# MSPM0G121X register map
Vendor: Texas Instruments; File version: Revised: 2025-10-06 10:58:04
CPU: CM0 r0p1, little endian, MPU, no FPU, 3 interrupt priority bits
Registers are 32-bit, read-write, reset 0x0 unless marked. A register's access mark holds for its fields unless they carry their own. Offsets are from the block's base; [hi:lo] are bit positions; lines under a group give offsets from that group; {n}, {i} and the like mark numbered series; 'fields as' and 'values as' point back to an identical list; <NAME> marks a mode.

## UC0_I2CC — PERIPHERALREGION
Base 0x40A26000
0x1000 UC0_I2CC_CLKDIV — Clock Divider
  [2:0] RATIO — Selects divide ratio of module clock Division factor 0 : DIV_BY_1 1 : DIV_BY_2 .... 63: DIV_BY_64
    0=DIV_BY_1 (Do not divide clock source); {v}=DIV_BY_{v+1} (Divide clock source by {v+1}) (v=1..7); {v}=DIV_BY_{v+1} (Divide clock source by 8) (v=60..63)
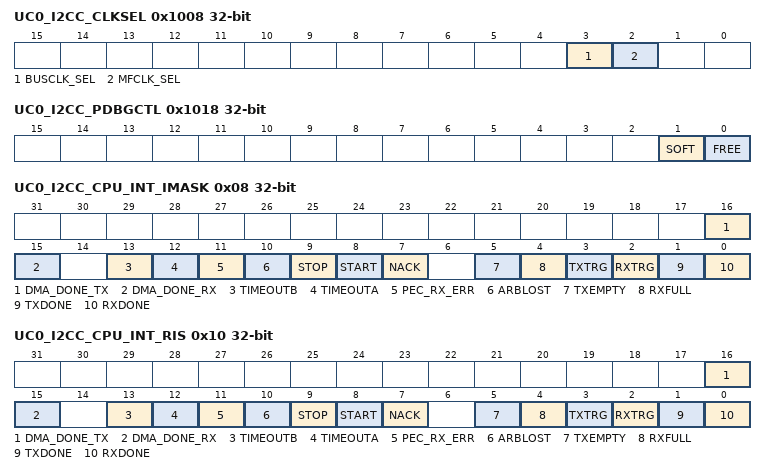
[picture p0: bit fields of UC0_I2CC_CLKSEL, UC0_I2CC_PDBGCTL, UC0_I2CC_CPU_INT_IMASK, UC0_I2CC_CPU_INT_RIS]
0x1008 UC0_I2CC_CLKSEL — Clock Select for Ultra Low Power peripherals
  [3] BUSCLK_SEL — Selects BUS CLK as clock source if enabled
    0=DISABLE (Does not select this clock as a source); 1=ENABLE (Select this clock as a source)
  [2] MFCLK_SEL — Selects MFCLK as clock source if enabled
    values as BUSCLK_SEL
0x1018 UC0_I2CC_PDBGCTL — Peripheral Debug Control
  [1] SOFT — Soft halt boundary control. This function is only available, if [FREE] is set to 'STOP'
    0=DEPRECATED (Not supported); 1=DELAYED (The peripheral blocks the debug freeze until it has reached a boundary where it can resume without corruption)
  [0] FREE — Free run control
    0=STOP (The peripheral freezes functionality while the Core Halted input is asserted and resumes when it is deasserted.); 1=RUN (The peripheral ignores the state of the Core Halted input)
{0x1020+0x2C*i} UC0_I2CC_CPU_INT[{i}] (i=0..0) group
  0x00 UC0_I2CC_IIDX ro — Interrupt index
    [7:0] STAT — I2C Module Interrupt Vector Value. This register provides the highes priority interrupt index. A read clears the corresponding interrupt flag in RIS and MISC. 15h-1Fh = Reserved
      0=NO_INTR (No interrupt pending); 1=RXDONEFG (Data received); 2=TXDONEFG (data transmitted); 3=RXTRG (Receive Trigger); 4=TXTRG (Transmit Trigger); 5=RXFULL (RX FIFO FULL Event/interrupt pending); 6=TXEMPTY (Transmit FIFO/Buffer Empty Event/interrupt pending); 8=NACKFG (Address/Data NACK); 9=STARTFG (Start Event); 10=STOPFG (Stop Event); 11=ARBLOSTFG (Arbitration Lost); 12=PEC_RX_ERR (PEC Receive Error Event); 13=TIMEOUTA (Timeout A Event); 14=TIMEOUTB (Timeout B Event); 16=DMA_DONE_RX (DMA DONE on Channel RX); 17=DMA_DONE_TX (DMA DONE on Channel TX); 19=DMA_PREIRQ_RX (DMA PRE IRQ INTERRUPT); 20=DMA_PREIRQ_TX (DMA PRE IRQ INTERRUPT)
  0x08 UC0_I2CC_CPU_INT_IMASK — Interrupt mask
    [16] DMA_DONE_TX — DMA Done on Event Channel TX
      0=CLR (Interrupt disabled); 1=SET (Set Interrupt Mask)
    [15] DMA_DONE_RX — DMA Done on Event Channel RX
      0=CLR (Interrupt disabled); 1=SET (Set Interrupt Mask)
    [13] TIMEOUTB — Timeout B Interrupt
      0=CLR (Clear Interrupt Mask); 1=SET (Set Interrupt Mask)
    [12] TIMEOUTA — TIMEOUTA interrupt
      0=CLR (Clear Interrupt Mask); 1=SET (Set Interrupt Mask)
    [11] PEC_RX_ERR — RX Pec Error Interrupt
      0=CLR (Clear Interrupt Mask); 1=SET (Set Interrupt Mask)
    [10] ARBLOST — Arbitration Lost interrupt
      0=CLR (Clear Interrupt Mask); 1=SET (Set Interrupt Mask)
    [9] STOP — STOP interrupt
      0=CLR (Clear Interrupt Mask); 1=SET (Set Interrupt Mask)
    [8] START — START interrupt
      0=CLR (Clear Interrupt Mask); 1=SET (Set Interrupt Mask)
    [7] NACK — NACK interrupt
      0=CLR (Clear Interrupt Mask); 1=SET (Set Interrupt Mask)
    [5] TXEMPTY — Transmit FIFO/Buffer Empty interrupt.
      0=CLR (Clear Interrupt Mask); 1=SET (Set Interrupt Mask)
    [4] RXFULL — RXFIFO full event
      0=CLR (Clear Interrupt Mask); 1=SET (Set Interrupt Mask)
    [3] TXTRG — Transmit Trigger
      0=CLR (Clear Interrupt Mask); 1=SET (Set Interrupt Mask)
    [2] RXTRG — Receive Trigger
      0=CLR (Clear Interrupt Mask); 1=SET (Set Interrupt Mask)
    [1] TXDONE — Transmit Transaction completed Interrupt
      0=CLR (Clear Interrupt Mask); 1=SET (Set Interrupt Mask)
    [0] RXDONE — RXDONE interrupt
      0=CLR (Clear Interrupt Mask); 1=SET (Set Interrupt Mask)
  0x10 UC0_I2CC_CPU_INT_RIS ro — Raw interrupt status
    [16] DMA_DONE_TX — DMA Done on Event Channel TX
      0=CLR (Interrupt disabled); 1=SET (Set Interrupt Mask)
    [15] DMA_DONE_RX — DMA Done on Event Channel RX
      0=CLR (Interrupt disabled); 1=SET (Set Interrupt Mask)
    [13] TIMEOUTB — Timeout B Interrupt
      0=CLR (Interrupt did not occur); 1=SET (Interrupt occured)
    [12] TIMEOUTA — Timeout A Interrupt
      0=CLR (Interrupt did not occur); 1=SET (Set Interrupt Mask)
    [11] PEC_RX_ERR — Receive PEC Error Interrupt: set when the calculated PEC does not match received PEC
      0=CLR (Interrupt did not occur); 1=SET (Interrupt Occured)
    [10] ARBLOST — Arbitration Lost Interrupt: in multi-controller systems, when this controller loses out during arbitration
      0=CLR (Interrupt did not occur); 1=SET (Set Interrupt Mask)
    [9] STOP — STOP Detection Interrupt
      0=CLR (Interrupt did not occur); 1=SET (Set Interrupt Mask)
    [8] START — START Detection Interrupt
      0=CLR (Interrupt did not occur); 1=SET (Set Interrupt Mask)
    [7] NACK — Address/Data NACK Interrupt: set when address or data nack is received
      0=CLR (Interrupt did not occur); 1=SET (Set Interrupt Mask)
    [5] TXEMPTY — Transmit FIFO Empty: set when Transmit FIFO is empty
      0=CLR (Interrupt did not occur); 1=SET (Interrupt occured)
    [4] RXFULL — RXFIFO full event. This interrupt is set when receive FIFO is full.
      0=CLR (Interrupt did not occur); 1=SET (Interrupt occured)
    [3] TXTRG — Transmit Trigger When FIFO is present, as per IFLS settings When FIFO is not present, trigger when transmit buffer is empty
      0=CLR (Clear Interrupt Mask); 1=SET (Set Interrupt Mask)
    [2] RXTRG — Receive Trigger When FIFO is present, as per IFLS settings when FIFO is not present, this indicates when buffer is full
      0=CLR (Clear Interrupt Mask); 1=SET (Set Interrupt Mask)
    [1] TXDONE — Transmit Done Interrupt: TXDONE interrupt is raised when a burst length completes Or, in case of quick command, when a quick command with R/Wn bit set to '0'
      0=CLR (Interrupt did not occur); 1=SET (Set Interrupt Mask)
    [0] RXDONE — Receive Done Interrupt: RXDONE interrupt is raised when a burst length completes Or, in case of quick command, when a quick command with R/Wn bit set to '1'
      0=CLR (Interrupt did not occur); 1=SET (Set Interrupt Mask)
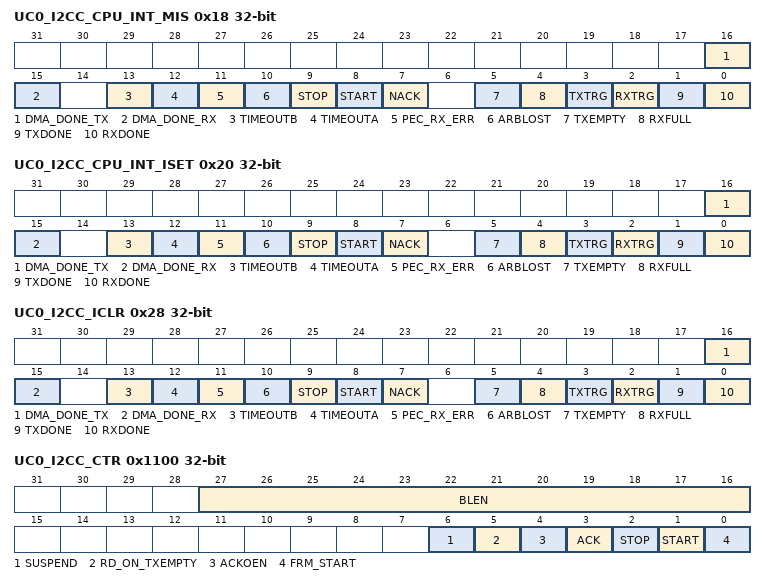
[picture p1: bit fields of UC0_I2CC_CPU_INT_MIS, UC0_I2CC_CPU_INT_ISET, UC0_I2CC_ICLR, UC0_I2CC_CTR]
  0x18 UC0_I2CC_CPU_INT_MIS ro — Masked interrupt status
    [16] DMA_DONE_TX — DMA Done on Event Channel TX
      0=CLR (Interrupt disabled); 1=SET (Set Interrupt Mask)
    [15] DMA_DONE_RX — DMA Done on Event Channel RX
      0=CLR (Interrupt disabled); 1=SET (Set Interrupt Mask)
    [13] TIMEOUTB — Timeout B Interrupt
      0=CLR (Clear interrupt mask); 1=SET (Set interrupt mask)
    [12] TIMEOUTA — Timeout A Interrupt
      0=CLR (Interrupt did not occur); 1=SET (Set Interrupt Mask)
    [11] PEC_RX_ERR — RX Pec Error Interrupt
      0=CLR (Clear interrupt mask); 1=SET (Set interrupt mask)
    [10] ARBLOST — Arbitration Lost Interrupt
      0=CLR (Interrupt did not occur); 1=SET (Set Interrupt Mask)
    [9] STOP — STOP Detection Interrupt
      0=CLR (Interrupt did not occur); 1=SET (Set Interrupt Mask)
    [8] START — START Detection Interrupt
      0=CLR (Interrupt did not occur); 1=SET (Set Interrupt Mask)
    [7] NACK — Address/Data NACK Interrupt
      0=CLR (Interrupt did not occur); 1=SET (Set Interrupt Mask)
    [5] TXEMPTY — Transmit FIFO Empty masked interrupt. This interrupt is set if all data in the Transmit FIFO have been shifted out and the transmit goes into idle mode.
      0=CLR (Interrupt did not occur); 1=SET (Interrupt occured)
    [4] RXFULL — Masked RXFIFO full event
      0=CLR (Interrupt did not occur); 1=SET (Interrupt occured)
    [3] TXTRG — Transmit Trigger
      0=CLR (Clear Interrupt Mask); 1=SET (Set Interrupt Mask)
    [2] RXTRG — Receive Trigger
      0=CLR (Clear Interrupt Mask); 1=SET (Set Interrupt Mask)
    [1] TXDONE — Transmit Transaction completed Interrupt
      0=CLR (Interrupt did not occur); 1=SET (Set Interrupt Mask)
    [0] RXDONE — Receive Data Interrupt
      0=CLR (Interrupt did not occur); 1=SET (Set Interrupt Mask)
  0x20 UC0_I2CC_CPU_INT_ISET wo — Interrupt set
    [16] DMA_DONE_TX — DMA Done on Event Channel TX
      0=NO_EFFECT (Interrupt disabled); 1=SET (Set Interrupt Mask)
    [15] DMA_DONE_RX — DMA Done on Event Channel RX
      0=NO_EFFECT (Interrupt disabled); 1=SET (Set Interrupt Mask)
    [13] TIMEOUTB — Timeout B Interrupt
      0=NO_EFFECT (Writing 0 has no effect); 1=SET (Set interrupt)
    [12] TIMEOUTA — Timeout A interrupt
      0=NO_EFFECT (Writing 0 has no effect); 1=SET (Set Interrupt Mask)
    [11] PEC_RX_ERR — RX Pec Error Interrupt
      0=NO_EFFECT (Writing 0 has no effect); 1=SET (Set interrupt)
    [10] ARBLOST — Arbitration Lost Interrupt
      values as TIMEOUTA
    [9] STOP — STOP Detection Interrupt
      values as TIMEOUTA
    [8] START — START Detection Interrupt
      values as TIMEOUTA
    [7] NACK — Address/Data NACK Interrupt
      values as TIMEOUTA
    [5] TXEMPTY — Transmit FIFO Empty interrupt mask. This interrupt is set if all data in the Transmit FIFO have been shifted out and the transmit goes into idle mode.
      0=NO_EFFECT (Writing 0 has no effect); 1=SET (Set Interrupt)
    [4] RXFULL — RXFIFO full event.
      0=NO_EFFECT (Writing 0 has no effect); 1=SET (Set Interrupt)
    [3] TXTRG — Transmit Trigger
      0=NO_EFFECT (Clear Interrupt Mask); 1=SET (Set Interrupt Mask)
    [2] RXTRG — Receive Trigger
      values as TXTRG
    [1] TXDONE — Transmit Transaction completed Interrupt
      values as TIMEOUTA
    [0] RXDONE — Receive Data Interrupt Signals that a byte has been received
      values as TIMEOUTA
  0x28 UC0_I2CC_ICLR wo — Interrupt clear
    [16] DMA_DONE_TX — DMA Done on Event Channel TX
      0=NO_EFFECT (Interrupt disabled); 1=CLR (Set Interrupt Mask)
    [15] DMA_DONE_RX — DMA Done on Event Channel RX
      0=NO_EFFECT (Interrupt disabled); 1=CLR (Set Interrupt Mask)
    [13] TIMEOUTB — Timeout B Interrupt
      0=NO_EFFECT (Writing 0 has no effect); 1=CLR (Clear Interrupt)
    [12] TIMEOUTA — Timeout A interrupt
      0=NO_EFFECT (Writing 0 has no effect); 1=CLR (Set Interrupt Mask)
    [11] PEC_RX_ERR — RX Pec Error Interrupt
      values as TIMEOUTB
    [10] ARBLOST — Arbitration Lost Interrupt
      values as TIMEOUTA
    [9] STOP — STOP Detection Interrupt
      values as TIMEOUTA
    [8] START — START Detection Interrupt
      values as TIMEOUTA
    [7] NACK — Address/Data NACK Interrupt
      values as TIMEOUTA
    [5] TXEMPTY — Transmit FIFO Empty interrupt mask. This interrupt is set if all data in the Transmit FIFO have been shifted out and the transmit goes into idle mode.
      values as TIMEOUTB
    [4] RXFULL — RXFIFO full event.
      values as TIMEOUTB
    [3] TXTRG — Transmit FIFO Trigger
      0=NO_EFFECT (Clear Interrupt Mask); 1=CLR (Set Interrupt Mask)
    [2] RXTRG — Receive Trigger
      values as TXTRG
    [1] TXDONE — Transmit Transaction completed Interrupt
      values as TIMEOUTA
    [0] RXDONE — Receive Data Interrupt Signals that a byte has been received
      values as TIMEOUTA
{0x1050+0x24*i} UC0_I2CC_DMA_TRIG1[{i}] (i=0..0) group
  0x08 UC0_I2CC_DMA_TRIG1_IMASK — Interrupt mask
    [2] RXTRG — Receive Trigger
      0=CLR (Clear Interrupt Mask); 1=SET (Set Interrupt Mask)
  0x10 UC0_I2CC_DMA_TRIG1_RIS ro — Raw interrupt status
    [2] RXTRG — Receive Trigger When FIFO is present, trigger when RX FIFO contains >= defined bytes when FIFO is not present, this indicates when buffer is full
      0=CLR (Clear Interrupt Mask); 1=SET (Set Interrupt Mask)
  0x18 UC0_I2CC_DMA_TRIG1_MIS ro — Masked interrupt status
    fields as UC0_I2CC_DMA_TRIG1[0].UC0_I2CC_DMA_TRIG1_IMASK
  0x20 UC0_I2CC_DMA_TRIG1_ISET wo — Interrupt set
    [2] RXTRG — Receive Trigger
      values as UC0_I2CC_CPU_INT[0].UC0_I2CC_CPU_INT_ISET.TXTRG
{0x1080+0x24*i} UC0_I2CC_DMA_TRIG0[{i}] (i=0..0) group
  0x08 UC0_I2CC_DMA_TRIG0_IMASK — Interrupt mask
    [3] TXTRG — Transmit Trigger
      0=CLR (Clear Interrupt Mask); 1=SET (Set Interrupt Mask)
  0x10 UC0_I2CC_DMA_TRIG0_RIS ro — Raw interrupt status
    fields as UC0_I2CC_DMA_TRIG0[0].UC0_I2CC_DMA_TRIG0_IMASK
  0x18 UC0_I2CC_DMA_TRIG0_MIS ro — Masked interrupt status
    fields as UC0_I2CC_DMA_TRIG0[0].UC0_I2CC_DMA_TRIG0_IMASK
  0x20 UC0_I2CC_DMA_TRIG0_ISET wo — Interrupt set
    [3] TXTRG — Transmit Trigger
      values as UC0_I2CC_CPU_INT[0].UC0_I2CC_CPU_INT_ISET.TXTRG
0x10E4 UC0_I2CC_INTCTL wo — Interrupt control register
  [0] INTEVAL — Writing a 1 to this field re-evaluates the interrupt sources.
    0=DISABLE (The interrupt or event line is disabled.); 1=EVAL (The interrupt or event line is in software mode. Software must clear the RIS.)
0x1100 UC0_I2CC_CTR — Control Register
  [27:16] BLEN — I2C transaction length This field contains the programmed length of bytes of the Transaction.
  [6] SUSPEND — Suspend external communication
    0=DISABLE (Functional mode resumed); 1=ENABLE (External communication suspended)
  [5] RD_ON_TXEMPTY — Read on TX Empty
    0=DISABLE (No special behavior); 1=ENABLE (When 1 the Controller will transmit all bytes from the TX FIFO before continuing with the programmed Burst Run Read. If the DIR is not set to Read in the MSA then this bit is ignored. The Start must be set in the MCTR for proper I2C protocol. The Controller will first send the Start Condition, I2C Address with R/W bit set to write, before sending the bytes in the TX FIFO. When the TX FIFO is empty, the I2C transaction will continue as programmed in MTCR and MSA without sending a Stop Condition. This is intended to be used to perform simple I2C command based reads transition that will complete after initiating them without having to get an interrupt to turn the bus around.)
  [4] ACKOEN — ACK overrride Enable
    0=DISABLE (No special behavior); 1=ENABLE (When 1 and the Controller is receiving data and the number of bytes indicated in MBLEN have been received, the state machine will generate an rxdone interrupt and wait at the start of the ACK for FW to indicate if an ACK or NACK should be sent. The ACK or NACK is selected by writing the MCTR register and setting ACK accordingly. The other fields in this register can also be written at this time to continue on with the transaction. If a NACK is sent the state machine will automatically send a Stop.)
  [3] ACK — Data Acknowledge Enable. Software needs to configure this bit to send the ACK or NACK. See field decoding in Table: MCTR Field decoding.
    0=DISABLE (The last received data byte of a transaction is not acknowledged automatically .); 1=ENABLE (The last received data byte of a transaction is acknowledged automatically .)
  [2] STOP — Generate STOP
    0=DISABLE (The controller does not generate the STOP condition.); 1=ENABLE (The controller generates the STOP condition. See field decoding in Table: MCTR Field decoding.)
  [1] START — Generate START
    0=DISABLE (The controller does not generate the START condition.); 1=ENABLE (The controller generates the START or repeated START condition. See field decoding in Table: MCTR Field decoding.)
  [0] FRM_START — Start Transfer
    0=DISABLE (In standard mode, this encoding means the Controller is unable to transmit or receive data.); 1=ENABLE (The Controller is able to transmit or receive data. See field decoding in Table: MCTR Field decoding.)
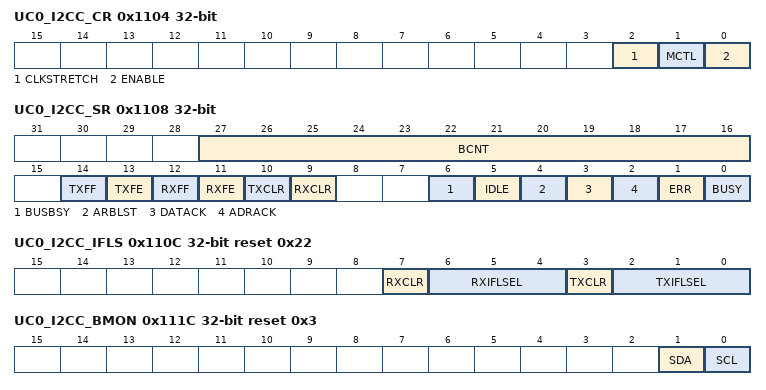
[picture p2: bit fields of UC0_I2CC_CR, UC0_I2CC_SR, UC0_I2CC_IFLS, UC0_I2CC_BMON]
0x1104 UC0_I2CC_CR — Configuration
  [2] CLKSTRETCH — Clock Stretching. This bit controls the support for clock stretching of the I2C bus.
    0=DISABLE (Disables the clock stretching detection. This can be disabled if no Target on the bus does support clock stretching, so that the maximum speed on the bus can be reached.); 1=ENABLE (Enables the clock stretching detection. Enabling the clock stretching ensures compliance to the I2C standard but could limit the speed due the clock stretching.)
  [1] MCTL — MultiController mode. In MultiController mode the SCL high time counts once the SCL line has been detected high. If this is not enabled the high time counts as soon as the SCL line has been set high by the I2C controller.
    0=DISABLE (Disable MultiController mode.); 1=ENABLE (Enable MultiController mode.)
  [0] ENABLE — Enable module. After this bit has been set, it should not be set again unless it has been cleared by writing a 0 or by a reset, otherwise transfer failures may occur.
    0=DISABLE (Disables operation.); 1=ENABLE (Enables operation.)
0x1108 UC0_I2CC_SR ro — Status Register
  [27:16] BCNT — Transaction Count This field contains the current count-down value of the transaction.
  [14] TXFF — Transmit FIFO Full The meaning of this bit depends on the state of the FEN bit in the CTL0 register.
    0=CLEARED (The transmitter is not full.); 1=SET (If the FIFO is disabled (FEN is 0), the transmit holding register is full. If the FIFO is enabled (FEN is 1), the transmit FIFO is full.)
  [13] TXFE — Transmit FIFO Empty The meaning of this bit depends on the state of the FEN bit in the CTL0 register.
    0=CLEARED (The transmitter has data to transmit.); 1=SET (If the FIFO is disabled (FEN is 0), the transmit holding register is empty. If the FIFO is enabled (FEN is 1), the transmit FIFO is empty.)
  [12] RXFF — Receive FIFO Full The meaning of this bit depends on the state of the FEN bit in the CTL0 register.
    0=CLEARED (The receiver can receive data.); 1=SET (If the FIFO is disabled (FEN is 0), the receive holding register is full. If the FIFO is enabled (FEN is 1), the receive FIFO is full.)
  [11] RXFE — Receive FIFO Empty The meaning of this bit depends on the state of the FEN bit in the CTL0 register.
    0=CLEARED (The receiver is not empty.); 1=SET (If the FIFO is disabled (FEN is 0), the receive holding register is empty. If the FIFO is enabled (FEN is 1), the receive FIFO is empty.)
  [10] TXCLR — TX FIFO Clear Status
    0=CLEARED (FIFO is not cleared); 1=SET (FIFO clear is complete)
  [9] RXCLR — RX FIFO Clear Status
    values as TXCLR
  [6] BUSBSY — I2C Bus is Busy Controller State Machine will wait until this bit to be cleared before starting a transaction. When first enabling the Controller in multi Controller environments, FW should wait for one I2C clock period after setting ACTIVE high before writing to the CTR register to start the transaction so that if SCL goes low it will trigger the BUSBSY.
    0=CLEARED (The I2C bus is idle.); 1=SET ('This Status bit is set on a START or when SCL goes low. It is cleared on a STOP, or when a SCL high bus busy timeout occurs and SCL and SDA are both high. This status is cleared when the ACTIVE bit is low. Note that the Controller State Machine will wait until this bit is cleared before starting an I2C transaction. When first enabling the Controller in multi Controller environments, FW should wait for one I2C clock period after setting ACTIVE high before writing to the MTCR register to start the transaction so that if SCL goes low it will trigger the BUSBSY.)
  [5] IDLE — I2C Idle
    0=CLEARED (The I2C controller is not idle.); 1=SET (The I2C controller is idle.)
  [4] ARBLST — Arbitration Lost
    0=CLEARED (The I2C controller won arbitration.); 1=SET (The I2C controller lost arbitration.)
  [3] DATACK — Acknowledge Data
    0=CLEARED (The transmitted data was acknowledged); 1=SET (The transmitted data was not acknowledged.)
  [2] ADRACK — Acknowledge Address
    0=CLEARED (The transmitted address was acknowledged); 1=SET (The transmitted address was not acknowledged.)
  [1] ERR — Error The error can be from the Target address not being acknowledged or the transmit data not being acknowledged.
    0=CLEARED (No error was detected on the last operation.); 1=SET (An error occurred on the last operation.)
  [0] BUSY — FSM Busy The BUSY bit is set during an ongoing transaction, so is set during the transmit/receive of the amount of data set in MBLEN including START, RESTART, Address and STOP signal generation when required for the current transaction.
    0=CLEARED (The controller is idle.); 1=SET (The controller is busy.)
0x110C UC0_I2CC_IFLS reset 0x22 — Interrupt FIFO Level Select Register
  [7] RXCLR — RX FIFO CLEAR. Setting this bit will clear the RX FIFO contents.
    0=DISABLE (Disable FIFO clear); 1=ENABLE (Enable FIFO Clear)
  [6:4] RXIFLSEL — FIFO Level Select for generating events (interrupt/dma). Note: for undefined settings the default configuration is used.
    1=LVL_1_4 (RX FIFO >= 1/4 full); 2=LVL_1_2 (RX FIFO >= 1/2 full (default)); 3=LVL_3_4 (RX FIFO >= 3/4 full); 4=LVL_NOT_EMPTY (Opposite of empty); 5=LVL_FULL (RX FIFO is full); 6=LVL_ALMOST_FULL (RX_FIFO >= (MAX_FIFO_LEN -1)); 7=LVL_ALMOST_EMPTY (RX_FIFO <= 1)
  [3] TXCLR — TX FIFO CLEAR. Setting this bit will clear the TX FIFO contents.
    0=DISABLE (Disable FIFO clear); 1=ENABLE (Enable FIFO Clear)
  [2:0] TXIFLSEL — FIFO Level Select for generating events (interrupt/dma). Note: for undefined settings the default configuration is used.
    1=LVL_3_4 (TX FIFO <= 3/4 empty); 2=LVL_1_2 (TX FIFO <= 1/2 empty (default)); 3=LVL_1_4 (TX FIFO <= 1/4 empty); 4=LVL_NOT_FULL (Opposite of full); 5=LVL_EMPTY (TX FIFO is empty); 6=LVL_ALMOST_EMPTY (TX FIFO <= 1); 7=LVL_ALMOST_FULL (TX_FIFO >= (MAX_FIFO_LEN -1))
0x1110 UC0_I2CC_TPR reset 0x1 — Timer Period
  [6:0] TPR — Timer Period This field is used in the equation to configure SCL_PERIOD : SCL_PERIOD = (1 + TPR ) * (SCL_LP + SCL_HP ) * INT_CLK_PRD where: SCL_PRD is the SCL line period (I2C clock). TPR is the Timer Period register value (range of 1 to 127). SCL_LP is the SCL Low period (fixed at 6). SCL_HP is the SCL High period (fixed at 4). CLK_PRD is the functional clock period in ns.
0x1118 UC0_I2CC_GFCTL — I2C Glitch Filter Control
  [8] AGFEN — Analog Glitch Suppression Enable
    0=DISABLE (Analog Glitch Filter disable); 1=ENABLE (Analog Glitch Filter enable)
0x111C UC0_I2CC_BMON ro reset 0x3 — Bus Monitor
  [1] SDA — I2C SDA Status
    0=CLEARED (The I2CSDA signal is low.); 1=SET (The I2CSDA signal is high. Note: During and right after reset, the SDA pin is in GPIO input mode without the internal pull enabled. For proper I2C operation, the user should have the external pull-up resistor in place before starting any I2C operations.)
  [0] SCL — I2C SCL Status
    0=CLEARED (The I2CSCL signal is low.); 1=SET (The I2CSCL signal is high. Note: During and right after reset, the SCL pin is in GPIO input mode without the internal pull enabled. For proper I2C operation, the user should have the external pull-up resistor in place before starting any I2C operations.)
0x1120 UC0_I2CC_TXDATA wo — TXData
  [7:0] DATA — Transmit Data This byte contains the data to be transferred during the next transaction.
0x1124 UC0_I2CC_RXDATA ro — RXData
  [7:0] DATA — Received Data. This field contains the last received data.
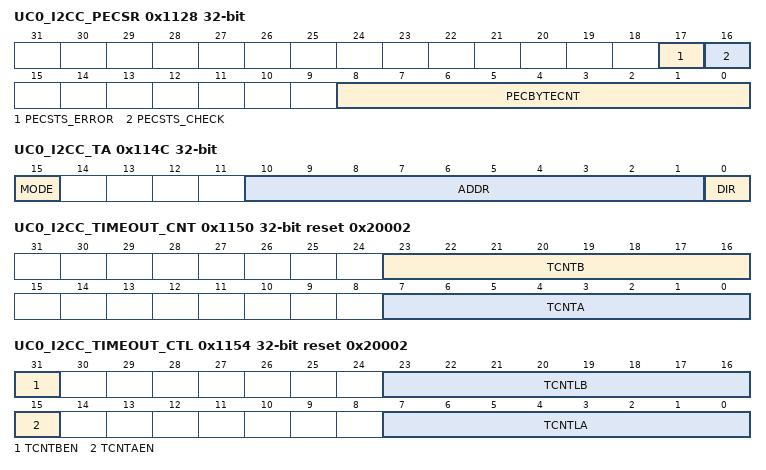
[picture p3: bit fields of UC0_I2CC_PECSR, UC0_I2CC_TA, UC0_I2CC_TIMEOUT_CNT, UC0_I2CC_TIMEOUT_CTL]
0x1128 UC0_I2CC_PECSR ro — PEC status register
  [17] PECSTS_ERROR — This status bit indicates if a PEC check error occurred in the transaction that occurred before the last Stop. Latched on Stop.
    0=CLEARED (Indicates PEC check error did not occurr in the transaction that occurred before the last Stop); 1=SET (Indicates if a PEC check error occurred in the transaction that occurred before the last Stop)
  [16] PECSTS_CHECK — This status bit indicates if the PEC was checked in the transaction that occurred before the last Stop. Latched on Stop.
    0=CLEARED (Indicates PEC was not checked in the transaction that occurred before the last Stop); 1=SET (Indicates if the PEC was checked in the transaction that occurred before the last Stop)
  [8:0] PECBYTECNT — PEC Byte Count This is the current PEC Byte Count of the Controller State Machine.
0x114C UC0_I2CC_TA — Target Address Register
  [15] MODE — This bit selects the adressing mode to be used When 0, 7-bit addressing is used. When 1, 10-bit addressing is used.
    0=7-bit addressing mode; 1=10-bit addressing mode
  [10:1] ADDR — I2C Target Address This field specifies bits A9 through A0 of the Target address. In 7-bit addressing mode as selected by MSA.MODE bit, the top 3 bits are don't care
  [0] DIR — Receive/Send The DIR bit specifies if the next operation is a Receive (High) or Transmit (Low). 0h = Transmit 1h = Receive
    0=TRANSMIT (in transmit mode.); 1=RECEIVE (is in receive mode.)
0x1150 UC0_I2CC_TIMEOUT_CNT ro reset 0x20002 — I2C Timeout Count Register
  [23:16] TCNTB — Timeout Count B Current Count: This field contains the upper 8 bits of a 12-bit current counter for timeout counter B
  [7:0] TCNTA — Timeout Count A Current Count: This field contains the upper 8 bits of a 12-bit current counter for timeout counter A
0x1154 UC0_I2CC_TIMEOUT_CTL reset 0x20002 — I2C Timeout Count Control Register
  [31] TCNTBEN — Timeout Counter B Enable
    0=DISABLE (Disable Timeout Counter B); 1=ENABLE (Enable Timeout Counter B)
  [23:16] TCNTLB — Timeout Count B Load: Counter B is used for SCL High Detection. This field contains the upper 8 bits of a 12-bit pre-load value for the Timeout B count. NOTE: The value of CNTLB must be greater than 1h. Each count is equal to 1* clock period. For example, with 10MHz functional clock one timeout period will be equal to1*100ns.
  [15] TCNTAEN — Timeout Counter A Enable
    values as TCNTBEN
  [7:0] TCNTLA — Timeout counter A load value Counter A is used for SCL low detection. This field contains the upper 8 bits of a 12-bit pre-load value for the Timeout A count. NOTE: The value of CNTLA must be greater than 1h. Each count is equal to 520 times the timeout period of functional clock. For example, with 8MHz functional clock and a 100KHz operating I2C clock, one timeout period will be equal to (1 / 8MHz) * 520 or 65 us.
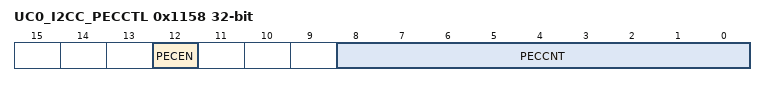
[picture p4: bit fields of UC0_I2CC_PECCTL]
0x1158 UC0_I2CC_PECCTL — I2C PEC control register
  [12] PECEN — PEC Enable This bit enables the SMB Packet Error Checking (PEC). When enabled the PEC is calculated on all bits except the Start, Stop, Ack and Nack. The PEC LSFR and the Byte Counter is set to 0 when the State Machine is in the IDLE state, which occur following a Stop or when a timeout occurs. The Counter is also set to 0 after the PEC byte is sent or received. Note that the NACK is automatically send following a PEC byte that results in a PEC error. The PEC Polynomial is x^8 + x^2 + x^1 + 1.
    0=DISABLE (PEC is disabled); 1=ENABLE (PEC is enabled)
  [8:0] PECCNT — PEC Count When this field is non zero, the number of I2C bytes are counted (Note that although the PEC is calculated on the I2C address it is not counted at a byte). When the byte count = PECCNT and the state machine is transmitting, the contents of the LSFR is loaded into the shift register instead of the byte received from the Tx FIFO. When the state machine is receiving, after the last bit of this byte is received the LSFR is checked and if it is non-zero, a PEC RX Error interrupt is generated. The I2C packet must be padded to include the PEC byte for both transmit and receive. In transmit mode the FIFO must be loaded with a dummy PEC byte. In receive mode the PEC byte will be passed to the Rx FIFO. In the normal Controller use case, FW would set PECEN=1 and PECCNT=SMB packet length (Not including Target Address byte, but including the PEC byte). FW would then configure DMA to allow the packet to complete unassisted and write MCTR to initiate the transaction. Note that when the byte count = PEC CNT, the byte count is reset to 0 and multiple PEC calculation can automatically occur within a single I2C transaction. Note that any write to the I2PECCTL Register will clear the current PEC Byte Count in the State Machine.

## UC5_I2CC — PERIPHERALREGION
Base 0x40A28000
Registers as UC0_I2CC (with UC0_I2CC read as UC5_I2CC).
